# DA1469x register map
Vendor: Dialog; Series: DA1469x; File version: 1.2
CPU: CM33 r1p0, little endian, no MPU, FPU, 3 interrupt priority bits
Registers are 32-bit, read-write, reset 0x0 unless marked. A register's access mark holds for its fields unless they carry their own. Offsets are from the block's base; [hi:lo] are bit positions; {n}, {i} and the like mark numbered series.

## QSPIC — QSPIC registers
Base 0x38000000
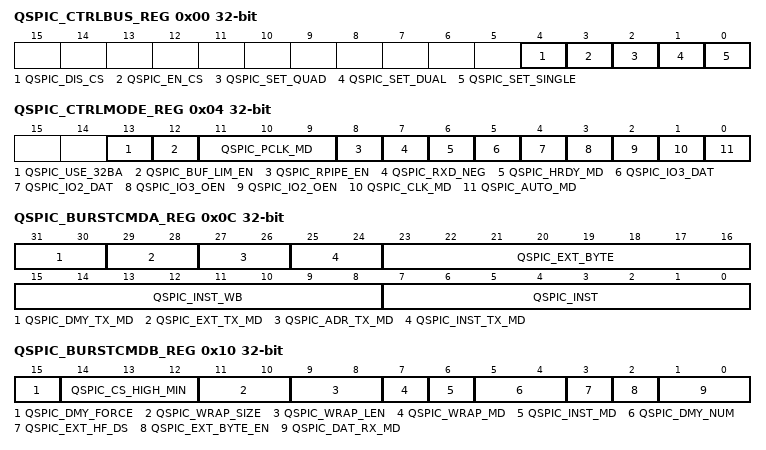
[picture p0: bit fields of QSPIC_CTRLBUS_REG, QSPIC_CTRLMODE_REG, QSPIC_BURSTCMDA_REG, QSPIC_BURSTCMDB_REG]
0x00 QSPIC_CTRLBUS_REG — SPI Bus control register for the Manual mode
  [4] QSPIC_DIS_CS wo — Write 1 to disable the chip select (active low) when the controller is in Manual mode.
  [3] QSPIC_EN_CS wo — Write 1 to enable the chip select (active low) when the controller is in Manual mode.
  [2] QSPIC_SET_QUAD wo — Write 1 to set the bus mode in Quad mode when the controller is in Manual mode.
  [1] QSPIC_SET_DUAL wo — Write 1 to set the bus mode in Dual mode when the controller is in Manual mode.
  [0] QSPIC_SET_SINGLE wo — Write 1 to set the bus mode in Single SPI mode when the controller is in Manual mode.
0x04 QSPIC_CTRLMODE_REG — Mode Control register
  [13] QSPIC_USE_32BA — Controls the length of the address that the external memory device uses. 0: The external memory device uses 24 bits address. 1: The external memory device uses 32 bits address. The controller uses this bit in order to decide the number of the address bytes that has to transfer to the external device during Auto mode.
  [12] QSPIC_BUF_LIM_EN — This bit has meaning only for the read in auto mode. Defines the behavior of the controller when the internal buffer is full and there are more data to be retrieved for the current burst. 0: The access in the flash device is not terminated when the internal buffer has no empty space. In this case the QSPI_SCK clock is blocked until to free space in the internal buffer. 1: The access in the flash device is terminated when the internal buffer has no empty space. A new access in the flash device will be initiated when will be requested addresses that are not present in the internal buffer. In both cases the access in the flash device is terminated when there is no any read request.
  [11:9] QSPIC_PCLK_MD — Read pipe clock delay relative to the falling edge of QSPI_SCK. Refer to QSPI Timing for timing parameters and recommended values: 0 to 7
  [8] QSPIC_RPIPE_EN — Controls the use of the data read pipe. 0: The read pipe is disabled; the sampling clock is defined according to the QSPIC_RXD_NEG setting. 1: The read pipe is enabled. The delay of the sampling clock is defined according to the QSPI_PCLK_MD setting. (Recommended)
  [7] QSPIC_RXD_NEG — Defines the clock edge that is used for the capturing of the received data, when the read pipe is not active (QSPIC_RPIPE_EN = 0). 0: Sampling of the received data with the positive edge of the QSPI_SCK 1: Sampling of the received data with the negative edge of the QSPI_SCK The internal QSPI_SCK clock that is used by the controller for the capturing of the received data has a skew in respect of the QSPI_SCK that is received by the external memory device. In order to be improved the timing requirements of the read path, the controller supports a read pipe register with programmable clock delay. See also the QSPIC_RPIPE_EN register.
  [6] QSPIC_HRDY_MD — This configuration bit is useful when the frequency of the QSPI clock is much lower than the clock of the AMBA bus, in order to not locks the AMBA bus for a long time. 0: Adds wait states via hready signal when an access is performed on the QSPIC_WRITEDATA, QSPIC_READDATA and QSPIC_DUMMYDATA registers. It is not needed to checked the QSPIC_BUSY of the QSPIC_STATUS_REG. 1: The controller don't adds wait states via the hready signal, when is performed access on the QSPIC_WRITEDATA, QSPIC_READDATA and QSPIC_DUMMYDATA registers. The QSPIC_BUSY bit of the QSPIC_STATUS_REG must be checked in order to be detected the completion of the requested access. It is applicable only when the controller is in Manual mode. In the case of the Auto mode, the controller always adds wait states via the hready signal.
  [5] QSPIC_IO3_DAT — The value of QSPI_IO3 pad if QSPI_IO3_OEN is 1
  [4] QSPIC_IO2_DAT — The value of QSPI_IO2 pad if QSPI_IO2_OEN is 1
  [3] QSPIC_IO3_OEN — QSPI_IO3 output enable. Use this only in SPI or Dual SPI mode to control /HOLD signal. When the Auto Mode is selected (QSPIC_AUTO_MD = 1) and the QUAD SPI is used, set this bit to zero. 0: The QSPI_IO3 pad is input. 1: The QSPI_IO3 pad is output.
  [2] QSPIC_IO2_OEN — QSPI_IO2 output enable. Use this only in SPI or Dual SPI mode to control /WP signal. When the Auto Mode is selected (QSPIC_AUTO_MD = 1) and the QUAD SPI is used, set this bit to zero. 0: The QSPI_IO2 pad is input. 1: The QSPI_IO2 pad is output.
  [1] QSPIC_CLK_MD — Mode of the generated QSPI_SCK clock 0: Use Mode 0 for the QSPI_CLK. The QSPI_SCK is low when QSPI_CS is high. 1: Use Mode 3 for the QSPI_CLK. The QSPI_SCK is high when QSPI_CS is high.
  [0] QSPIC_AUTO_MD — Mode of operation 0: The Manual Mode is selected. 1: The Auto Mode is selected. During an erasing the QSPIC_AUTO_MD goes in read only mode (see QSPIC_ERASE_EN)
0x08 QSPIC_RECVDATA_REG (reset mask 0x7FFFFFFF) — Received data for the Manual mode
  [31:0] QSPIC_RECVDATA ro — This register contains the received data when the QSPIC_READDATA_REG register is used in Manual mode, in order to be retrieved data from the external memory device and QSPIC_HRDY_MD=1 && QSPIC_BUSY=0.
0x0C QSPIC_BURSTCMDA_REG (reset mask 0x7FFFFFFF) — The way of reading in Auto mode (command register A)
  [31:30] QSPIC_DMY_TX_MD — It describes the mode of the SPI bus during the Dummy bytes phase. 0x0: Single SPI 0x1: Dual 0x2: Quad 0x3: Reserved
  [29:28] QSPIC_EXT_TX_MD — It describes the mode of the SPI bus during the Extra Byte phase. 0x0: Single SPI 0x1: Dual 0x2: Quad 0x3: Reserved
  [27:26] QSPIC_ADR_TX_MD — It describes the mode of the SPI bus during the address phase. 0x0: Single SPI 0x1: Dual 0x2: Quad 0x3: Reserved
  [25:24] QSPIC_INST_TX_MD — It describes the mode of the SPI bus during the instruction phase. 0x0: Single SPI 0x1: Dual 0x2: Quad 0x3: Reserved
  [23:16] QSPIC_EXT_BYTE — The value of an extra byte which will be transferred after address (only if QSPIC_EXT_BYTE_EN= 1). Usually this is the Mode Bits in Dual/Quad SPI I/O instructions.
  [15:8] QSPIC_INST_WB — IInstruction Value for Wrapping Burst. This value is the selected instruction when QSPIC_WRAP_MD is equal to 1 and the access is a wrapping burst of length and size described by the bit fields QSPIC_WRAP_LEN and QSPIC_WRAP_SIZE respectively.
  [7:0] QSPIC_INST — Instruction Value for Incremental Burst or Single read access. This value is the selected instruction at the cases of incremental burst or single read access. Also this value is used when a wrapping burst is not supported (QSPIC_WRAP_MD)
0x10 QSPIC_BURSTCMDB_REG — The way of reading in Auto mode (command register B)
  [15] QSPIC_DMY_FORCE — By setting this bit, the number of dummy bytes is forced to be equal to 3. In this case the QSPIC_DMY_NUM field is overruled and has no function. 0: The number of dummy bytes is controlled by the QSPIC_DMY_NUM field 1: Three dummy bytes are used. The QSPIC_DMY_NUM is overruled.
  [14:12] QSPIC_CS_HIGH_MIN — Between the transmissions of two different instructions to the flash memory, the SPI bus stays in idle state (QSPI_CS high) for at least this number of QSPI_SCK clock cycles. See the QSPIC_ERS_CS_HI register for some exceptions.
  [11:10] QSPIC_WRAP_SIZE — It describes the selected data size of a wrapping burst (QSPIC_WRAP_MD). 0x0: byte access (8-bits) 0x1: half word access (16 bits) 0x2: word access (32-bits) 0x3: Reserved
  [9:8] QSPIC_WRAP_LEN — It describes the selected length of a wrapping burst (QSPIC_WRAP_MD). 0x0: 4 beat wrapping burst 0x1: 8 beat wrapping burst 0x2: 16 beat wrapping burst 0x3: Reserved
  [7] QSPIC_WRAP_MD — Wrap mode 0: The QSPIC_INST is the selected instruction at any access. 1: The QSPIC_INST_WB is the selected instruction at any wrapping burst access of length and size described by the registers QSPIC_WRAP_LEN and QSPIC_WRAP_SIZE respectively. In all other cases the QSPIC_INST is the selected instruction. Use this feature only when the serial FLASH memory supports a special instruction for wrapping burst access.
  [6] QSPIC_INST_MD — Instruction mode 0: Transmit instruction at any burst access. 1: Transmit instruction only in the first access after the selection of Auto Mode.
  [5:4] QSPIC_DMY_NUM — Number of Dummy Bytes 0x0: Zero Dummy Bytes (Don't Send Dummy Bytes) 0x1: Send 1 Dummy Byte 0x2: Send 2 Dummy Bytes 0x3: Send 4 Dummy Bytes When QSPIC_DMY_FORCE is enabled, the QSPIC_DMY_NUM is overruled. In this case the number of dummy bytes is defined by the QSPIC_DMY_FORCE and is equal to 3, independent of the value of the QSPIC_DMY_NUM.
  [3] QSPIC_EXT_HF_DS — Extra Half Disable Output 0: if QSPIC_EXT_BYTE_EN=1, is transmitted the complete QSPIC_EXT_BYTE 1: if QSPIC_EXT_BYTE_EN=1, the output is disabled (hi-z) during the transmission of bits [3:0] of QSPIC_EXT_BYTE
  [2] QSPIC_EXT_BYTE_EN — Extra Byte Enable 0: Don't Send QSPIC_EXT_BYTE 1: Send QSPIC_EXT_BYTE
  [1:0] QSPIC_DAT_RX_MD — It describes the mode of the SPI bus during the data phase. 0x0: Single SPI 0x1: Dual 0x2: Quad 0x3: Reserved
0x14 QSPIC_STATUS_REG — The status register of the QSPI controller
  [0] QSPIC_BUSY ro — The status of the SPI Bus. 0: The SPI Bus is idle 1: The SPI Bus is active. Read data, write data or dummy data activity is in progress. Has meaning only in Manual mode and only when QSPIC_HRDY_MD = 1.
0x18 QSPIC_WRITEDATA_REG (reset mask 0x7FFFFFFF) — Write data to SPI Bus for the Manual mode
  [31:0] QSPIC_WRITEDATA wo — Writing to this register is generating a data transfer from the controller to the external memory device. The data written in this register, is then transferred to the memory using the selected mode of the SPI bus (SPI, Dual SPI, Quad SPI). The data size of the access to this register can be 32-bits / 16-bits/ 8-bits and is equal to the number of the transferred bits. This register has meaning only when the controller is in Manual mode.
0x1C QSPIC_READDATA_REG (reset mask 0x7FFFFFFF) — Read data from SPI Bus for the Manual mode
  [31:0] QSPIC_READDATA ro — A read access at this register generates a data transfer from the external memory device to the QSPIC controller. The data is transferred using the selected mode of the SPI bus (SPI, Dual SPI, Quad SPI). The data size of the access to this register can be 32-bits / 16-bits / 8-bits and is equal to the number of the transferred bits. This register has meaning only when the controller is in Manual mode.
0x20 QSPIC_DUMMYDATA_REG (reset mask 0x7FFFFFFF) — Send dummy clocks to SPI Bus for the Manual mode
  [31:0] QSPIC_DUMMYDATA wo — Writing to this register generates a number of clock pulses to the SPI bus. During the last clock of this activity in the SPI bus, the QSPI_IOx data pads are in hi-z state. The data size of the access to this register can be 32-bits / 16-bits/ 8-bits. The number of generated pulses is equal to: (size of AHB bus access) / (size of SPI bus). The size of SPI bus is equal to 1, 2 or 4 for Single, Dual or Quad SPI mode respectively. This register has meaning only when the controller is in Manual mode.
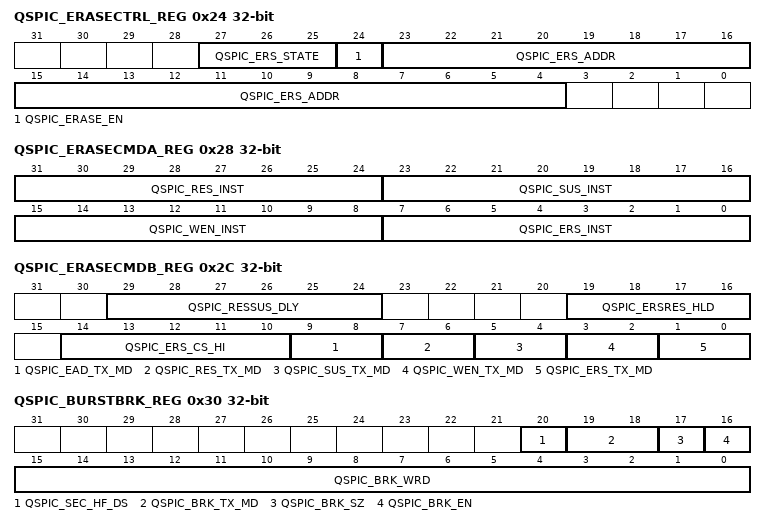
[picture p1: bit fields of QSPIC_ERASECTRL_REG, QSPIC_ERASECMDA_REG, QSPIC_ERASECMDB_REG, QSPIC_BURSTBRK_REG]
0x24 QSPIC_ERASECTRL_REG — QSPI Erase control register
  [27:25] QSPIC_ERS_STATE ro — It shows the progress of sector/block erasing (read only). 0x0: No Erase. 0x1: Pending erase request 0x2: Erase procedure is running 0x3: Suspended Erase procedure 0x4: Finishing the Erase procedure 0x5..0x7: Reserved
  [24] QSPIC_ERASE_EN — During Manual mode (QSPIC_AUTO_MD = 0). This bit is in read only mode. During Auto mode (QSPIC_AUTO_MD = 1). To request the erasing of the block/sector (QSPIC_ERS_ADDR, 12'b0) write 1 to this bit. This bit is cleared automatically with the end of the erasing. Until the end of erasing the QSPIC_ERASE_EN remains in read only mode. During the same period of time the controller remains in Auto Mode (QSPIC_AUTO_MD goes in read only mode).
  [23:4] QSPIC_ERS_ADDR — Defines the address of the block/sector that is requested to be erased. If QSPIC_USE_32BA = 0 (24 bits addressing), bits QSPIC_ERASECTRL_REG[23-12] determine the block/ sector address bits [23-12]. QSPIC_ERASECTRL_REG[11-4] are ignored by the controller. If QSPIC_USE_32BA = 1 (32 bits addressing) bits QSPIC_ERASECTRL_REG[23-4] determine the block / sectors address bits [31:12]
0x28 QSPIC_ERASECMDA_REG (reset mask 0x7FFFFFFF) — The way of erasing in Auto mode (command register A)
  [31:24] QSPIC_RES_INST — The code value of the erase resume instruction
  [23:16] QSPIC_SUS_INST — The code value of the erase suspend instruction.
  [15:8] QSPIC_WEN_INST — The code value of the write enable instruction.
  [7:0] QSPIC_ERS_INST — The code value of the erase instruction.
0x2C QSPIC_ERASECMDB_REG — The way of erasing in Auto mode (command register B)
  [29:24] QSPIC_RESSUS_DLY — Defines a timer that counts the minimum allowed delay between an erase suspend command and the previous erase resume command (or the initial erase command). 0: Dont wait. The controller starts immediately to suspend the erase procedure. 1..63: The controller waits for at least this number of 222kHz clock cycles before the suspension of erasing. Time starts counting after the end of the previous erase resume command (or the initial erase command)
  [19:16] QSPIC_ERSRES_HLD — The controller must stay without flash memory reading requests for this number of AMBA hclk clock cycles, before to perform the command of erase or erase resume 15 - 0
  [14:10] QSPIC_ERS_CS_HI — After the execution of instructions: write enable, erase, erase suspend and erase resume, the QSPI_CS remains high for at least this number of qspi bus clock cycles.
  [9:8] QSPIC_EAD_TX_MD — The mode of the QSPI Bus during the address phase of the erase instruction 0x0: Single 0x1: Dual 0x2: Quad 0x3: Reserved
  [7:6] QSPIC_RES_TX_MD — The mode of the QSPI Bus during the transmission of the resume instruction 0x0: Single 0x1: Dual 0x2: Quad 0x3: Reserved
  [5:4] QSPIC_SUS_TX_MD — The mode of the QSPI Bus during the transmission of the suspend instruction. 0x0: Single 0x1: Dual 0x2: Quad 0x3: Reserved
  [3:2] QSPIC_WEN_TX_MD — The mode of the QSPI Bus during the transmission of the write enable instruction. 0x0: Single 0x1: Dual 0x2: Quad 0x3: Reserved
  [1:0] QSPIC_ERS_TX_MD — The mode of the QSPI Bus during the instruction phase of the erase instruction 0x0: Single 0x1: Dual 0x2: Quad 0x3: Reserved
0x30 QSPIC_BURSTBRK_REG — Read break sequence in Auto mode
  [20] QSPIC_SEC_HF_DS — Disable output during the transmission of the second half (QSPIC_BRK_WRD[3:0]). Setting this bit is only useful if QSPIC_BRK_EN =1 and QSPIC_BRK_SZ= 1. 0: The controller drives the QSPI bus during the transmission of the QSPIC_BRK_WRD[3:0]. 1: The controller leaves the QSPI bus in Hi-Z during the transmission of the QSPIC_BRK_WORD[3:0].
  [19:18] QSPIC_BRK_TX_MD — The mode of the QSPI Bus during the transmission of the burst break sequence. 0x0: Single 0x1: Dual 0x2: Quad 0x3: Reserved
  [17] QSPIC_BRK_SZ — The size of Burst Break Sequence 0: One byte (Send QSPIC_BRK_WRD[15:8]) 1: Two bytes (Send QSPIC_BRK_WRD[15:0])
  [16] QSPIC_BRK_EN — Controls the application of a special command (read burst break sequence) that is used in order to force the device to abandon the continuous read mode. 0: The special command is not applied 1: The special command is applied This special command is applied by the controller to the external device under the following conditions: - the controller is in Auto mode - the QSPIC_INST_MD = 1 - the previous command that has been applied in the external device was read - the controller want to apply to the external device a command different than the read.
  [15:0] QSPIC_BRK_WRD — This is the value of a special command (read burst break sequence) that is applied by the controller to the external memory device, in order to force the memory device to abandon the continuous read mode.
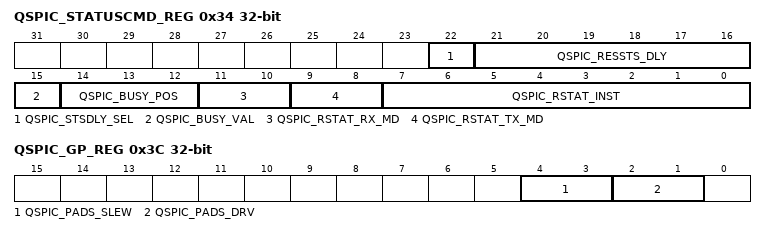
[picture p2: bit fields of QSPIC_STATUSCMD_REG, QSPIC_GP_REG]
0x34 QSPIC_STATUSCMD_REG — The way of reading the status of external device in Auto mode
  [22] QSPIC_STSDLY_SEL — Defines the timer which is used to count the delay that it has to wait before to read the FLASH Status Register, after an erase or an erase resume command. 0: The delay is controlled by the QSPIC_RESSTS_DLY which counts on the qspi clock. 1: The delay is controlled by the QSPIC_RESSUS_DLY which counts on the 222 kHz clock.
  [21:16] QSPIC_RESSTS_DLY — Defines a timer that counts the minimum required delay between the reading of the status register and of the previous erase or erase resume instruction. 0: Dont wait. The controller starts to reading the Flash memory status register immediately. 1..63: The controller waits for at least this number of QSPI_CLK cycles and afterwards it starts to reading the Flash memory status register. The timer starts to count after the end of the previous erase or erase resume command. The actual timer that will be used by the controller before the reading of the Flash memory status register is defined by the QSPIC_STSDLY_SEL.
  [15] QSPIC_BUSY_VAL — Defines the value of the Busy bit which means that the flash is busy. 0: The flash is busy when the Busy bit is equal to 0. 1: The flash is busy when the Busy bit is equal to 1.
  [14:12] QSPIC_BUSY_POS — It describes who from the bits of status represents the Busy bit (7 - 0).
  [11:10] QSPIC_RSTAT_RX_MD — The mode of the QSPI Bus during the receive status phase of the read status instruction 0x0: Single 0x1: Dual 0x2: Quad 0x3: Reserved
  [9:8] QSPIC_RSTAT_TX_MD — The mode of the QSPI Bus during the instruction phase of the read status instruction. 0x0: Single 0x1: Dual 0x2: Quad 0x3: Reserved
  [7:0] QSPIC_RSTAT_INST — The code value of the read status instruction. It is transmitted during the instruction phase of the read status instruction.
0x38 QSPIC_CHCKERASE_REG (reset mask 0x7FFFFFFF) — Check erase progress in Auto mode
  [31:0] QSPIC_CHCKERASE wo — Writing any value to this register during erasing, forces the controller to read the flash memory status register. Depending on the value of the Busy bit, it updates the QSPIC_ERASE_EN.
0x3C QSPIC_GP_REG — QSPI General Purpose control register
  [4:3] QSPIC_PADS_SLEW — QSPI pads slew rate control. Indicative values under certain conditions: 0: Rise=1.7 V/ns, Fall=1.9 V/ns (weak) 1: Rise=2.0 V/ns, Fall=2.3 V/ns 2: Rise=2.3 V/ns, Fall=2.6 V/ns 3: Rise=2.4 V/ns, Fall=2.7 V/ns (strong) Conditions: FLASH pin capacitance 6 pF, Vcc=1.8V, T=25C and Idrive=16mA.
  [2:1] QSPIC_PADS_DRV — QSPI pads drive current 0: 4 mA 1: 8 mA 2: 12 mA 3: 16 mA
0x40 QSPIC_UCODE_START (reset mask 0x7FFFFFFF) — QSPIC uCode memory
  [31:0] QSPIC_UCODE_X — The controller has a dedicated memory cell of 16 words x 32 bits that is used for the storing of the microcode that describes the initialization process of the external flash device. The first word (word 0) of this memory can be accessed by accessing the QSPIC_UCODE_START register. The next words can be accessed by accessing the QSPIC_UCODE_START + 4*X (X=1 .. 15).
0x80 QSPIC_CTR_CTRL_REG — Control register for the decryption engine of the QSPIC
  [0] QSPIC_CTR_EN — Controls the AES-CTR decryption feature of the QSPIC, which enables the decryption (on-the-fly) of the data that are retrieved from the flash memory device. 0: The AES-CTR decryption is disabled. 1: The controller will decrypt the content of the flash memory device that is placed in the address space that is defined by the QSPIC_CTR_SADDR_REG and QSPIC_CTR_EADDR_REG registers. The data that are placed outside the previous space are not decrypted by the QSPIC. The decryption is performed by using the AES-CTR algorithm. The AES key is defined by the QSPIC_CTR_KEY_x_y_REG registers and the nonce value by the QSPIC_CTR_NONCE_x_y_REG registers. This configuration bit has meaning only while the controller is in Auto mode. The on-the-fly decryption is not provided in Manual mode.
0x84 QSPIC_CTR_SADDR_REG (reset mask 0x7FFFFFFF) — Start address of the encrypted content in the QSPI flash
  [31:10] QSPIC_CTR_SADDR — Defines the bits [31:10] of the start address in the flash memory, where an encrypted image is placed. The bits [9:0] are considered always as zero. This has meaning only when the decryption is active. See also the register QSPIC_CTR_CTRL_REG[QSPIC_CTR_EN].
0x88 QSPIC_CTR_EADDR_REG reset 0x3FF (reset mask 0x7FFFFFFF) — End address of the encrypted content in the QSPI flash
  [31:10] QSPIC_CTR_EADDR — Defines the bits [31:10] of the end address in the flash memory, where an encrypted image is placed. The bits [9:0] are considered always as 0x3ff. This has meaning only when the decryption is active. See also the register QSPIC_CTR_CTRL_REG[QSPIC_CTR_EN].
0x8C QSPIC_CTR_NONCE_0_3_REG (reset mask 0x7FFFFFFF) — Nonce bytes 0 to 3 for the AES-CTR algorithm
  [31:0] QSPIC_CTR_NONCE_0_3 — Defines the 8 bytes of the nonce value (N0 - N7) that is used by the AES-CTR algorithm in order to be constructed the counter block (CTRB). The total size of the counter block is 128 bits or 16 bytes : CTRB0 CTRB1 CTRB2 CTRB3...CTRB14 CTRB15. The first 8 bytes (CTRB0 - CTRB7) of the counter block consisted by the nonce value. The next 8 bytes of the counter block (CTRB8-CTRB15), are produced automatically by the hardware based on the address offset inside the encrypted image, from where are retrieved the requested data. The mapping of the nonce bytes to the corresponding QSPIC_NONCE_X_Y_REG registers is the following : {CTRB0, CTRB1, CTRB2, CTRB3} = {N0, N1, N2, N3} = QSPIC_NONCE_0_3_REG[31:0] {CTRB4, CTRB5, CTRB6, CTRB7} = {N4, N5, N6, N7} = QSPIC_NONCE_4_7_REG[31:0] All these registers make sense only when QSPIC_CTR_CTRL_REG[QSPIC_CTR_EN] = 1.Do not perform access to an encrypted address range while the updating process of the nonce value is in progress.
0x90 QSPIC_CTR_NONCE_4_7_REG (reset mask 0x7FFFFFFF) — Nonce bytes 4 to 7 for the AES-CTR algorithm
  [31:0] QSPIC_CTR_NONCE_4_7 — See the description in the QSPIC_NONCE_0_3.
0x94 QSPIC_CTR_KEY_0_3_REG (reset mask 0x7FFFFFFF) — Key bytes 0 to 3 for the AES-CTR algorithm
  [31:0] QSPIC_CTR_KEY_0_3 wo — Defines the key that is used by the AES-CTR algorithm, when the on-the-fly decryption is enabled ( QSPIC_CTR_CTRL_REG[QSPIC_CTR_EN] = 1 ). The size of the decryption key is 256bits or 32 bytes : K0 K1 K2 K3...K30 K31. The mapping of the bytes to the corresponding QSPIC_CTR_KEY_X_Y_REG regisers is the following : {K0, K1, K2, K3} = QSPIC_CTR_KEY_0_3_REG[31:0] {K4, K5, K6, K7} = QSPIC_CTR_KEY_4_7_REG[31:0] {K8, K9, K10, K11} = QSPIC_CTR_KEY_8_11_REG[31:0] {K12, K13, K14, K15} = QSPIC_CTR_KEY_12_15_REG[31:0] {K16, K17, K18, K19} = QSPIC_CTR_KEY_16_19_REG[31:0] {K20, K21, K22, K23} = QSPIC_CTR_KEY_20_23_REG[31:0] {K24, K25, K26, K27} = QSPIC_CTR_KEY_24_27_REG[31:0] {K28, K29, K30, K31} = QSPIC_CTR_KEY_28_31_REG[31:0] All these registers make sense only when QSPIC_CTR_CTRL_REG[QSPIC_CTR_EN] = 1. Do not perform access to an encrypted address range while the updating process of the decryption key is in progress.
0x98 QSPIC_CTR_KEY_4_7_REG (reset mask 0x7FFFFFFF) — Key bytes 4 to 7 for the AES-CTR algorithm
  [31:0] QSPIC_CTR_KEY_4_7 wo — See the description in the QSPIC_CTR_KEY_0_3.
0x9C QSPIC_CTR_KEY_8_11_REG (reset mask 0x7FFFFFFF) — Key bytes 8 to 11 for the AES-CTR algorithm
  [31:0] QSPIC_CTR_KEY_8_11 wo — See the description in the QSPIC_CTR_KEY_0_3.
0xA0 QSPIC_CTR_KEY_12_15_REG (reset mask 0x7FFFFFFF) — Key bytes 12 to 15 for the AES-CTR algorithm
  [31:0] QSPIC_CTR_KEY_12_15 wo — See the description in the QSPIC_CTR_KEY_0_3.
0xA4 QSPIC_CTR_KEY_16_19_REG (reset mask 0x7FFFFFFF) — Key bytes 16 to 19 for the AES-CTR algorithm
  [31:0] QSPIC_CTR_KEY_16_19 wo — See the description in the QSPIC_CTR_KEY_0_3.
0xA8 QSPIC_CTR_KEY_20_23_REG (reset mask 0x7FFFFFFF) — Key bytes 20 to 23 for the AES-CTR algorithm
  [31:0] QSPIC_CTR_KEY_20_23 wo — See the description in the QSPIC_CTR_KEY_0_3.
0xAC QSPIC_CTR_KEY_24_27_REG (reset mask 0x7FFFFFFF) — Key bytes 24 to 27 for the AES-CTR algorithm
  [31:0] QSPIC_CTR_KEY_24_27 wo — See the description in the QSPIC_CTR_KEY_0_3.
0xB0 QSPIC_CTR_KEY_28_31_REG (reset mask 0x7FFFFFFF) — Key bytes 28 to 31 for the AES-CTR algorithm
  [31:0] QSPIC_CTR_KEY_28_31 wo — See the description in the QSPIC_CTR_KEY_0_3.
